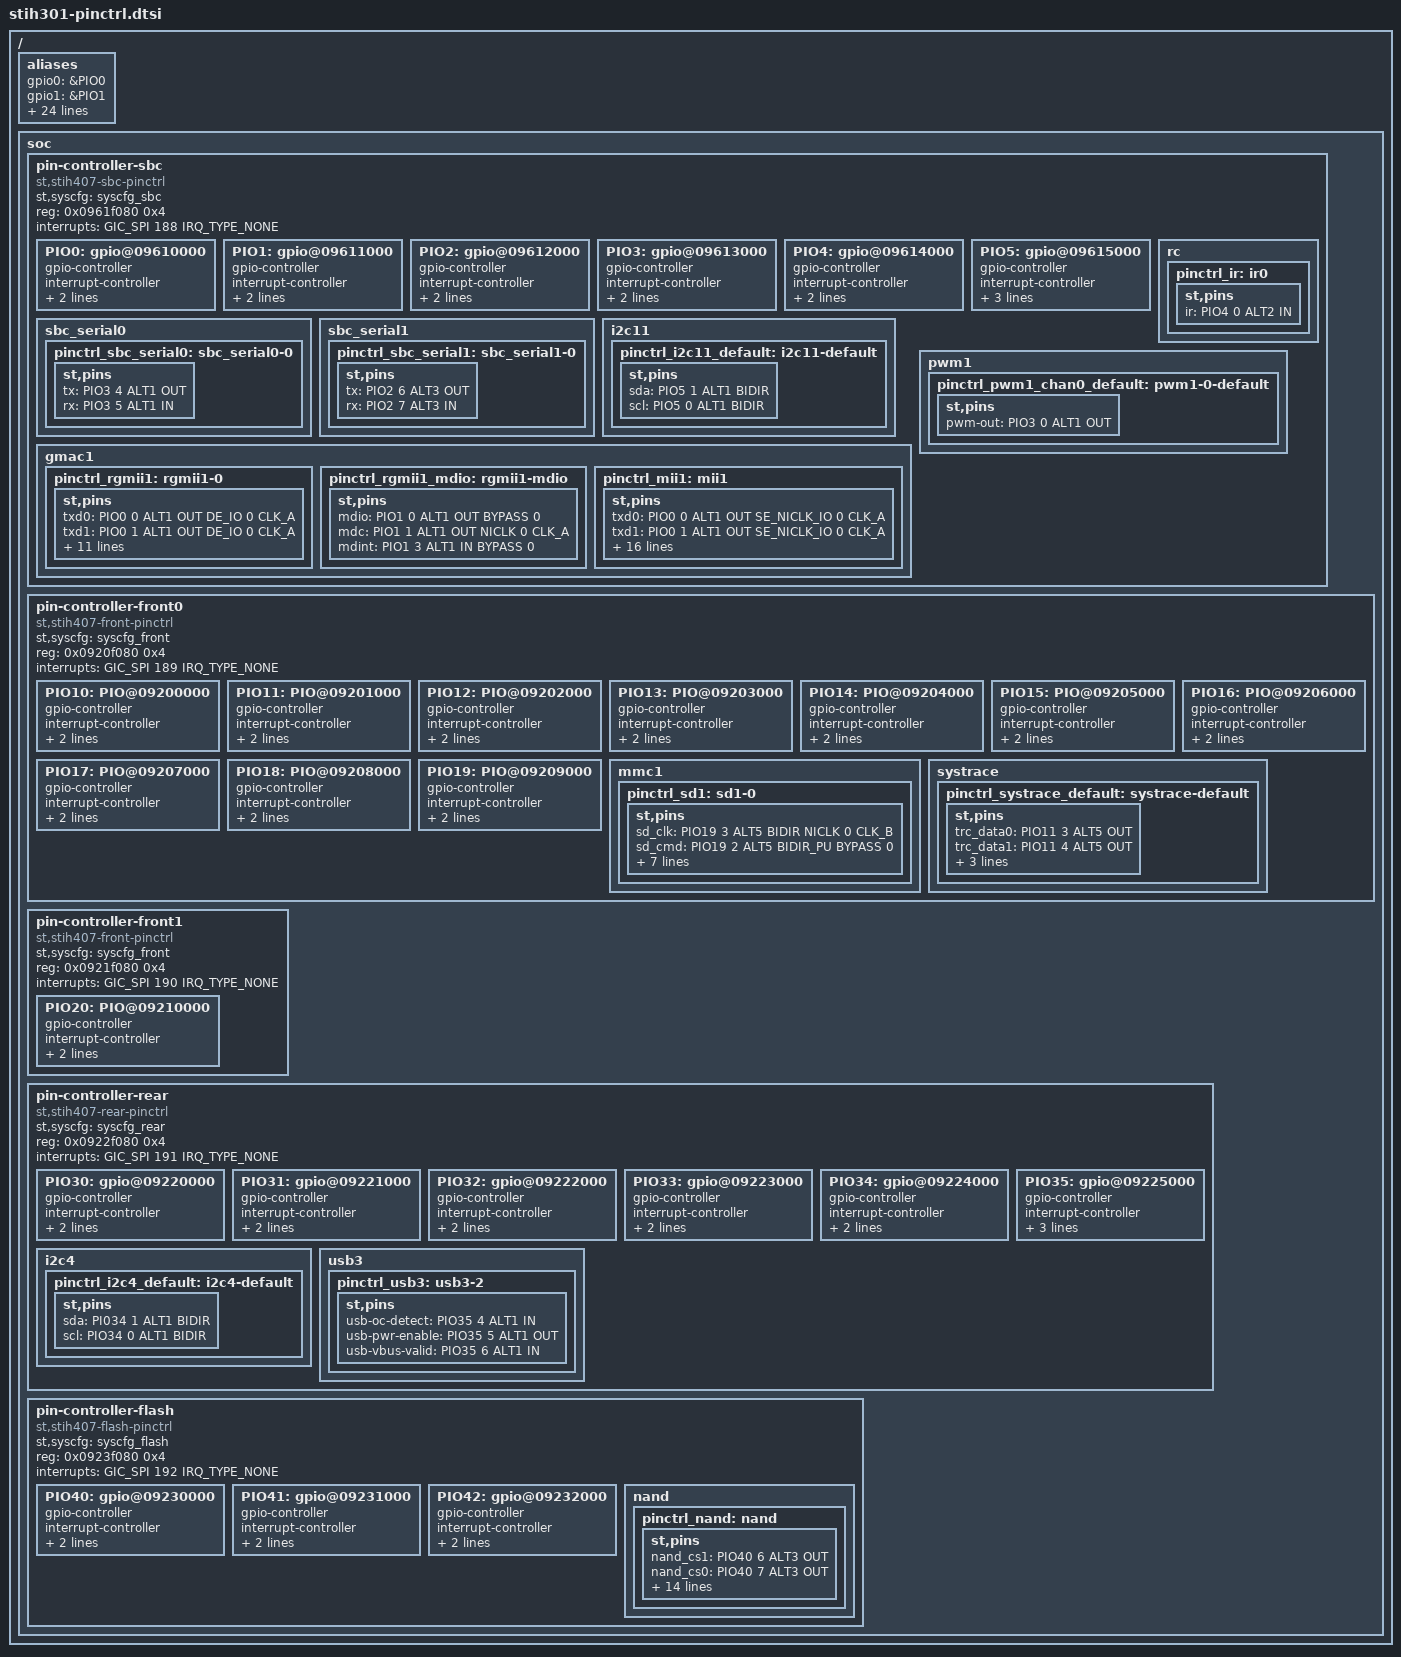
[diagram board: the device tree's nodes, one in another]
/*
 * Copyright (C) 2014 STMicroelectronics Limited.
 * Author: Amelie Herault <amelie.herault@st.com>
 *
 * This program is free software; you can redistribute it and/or modify
 * it under the terms of the GNU General Public License version 2 as
 * publishhed by the Free Software Foundation.
 */
#include <dt-bindings/pinctrl/st-pincfg.h>
#include <dt-bindings/interrupt-controller/arm-gic.h>
/ {

	aliases {
		/* 0-5: PIO_SBC */
		gpio0 = &PIO0;
		gpio1 = &PIO1;
		gpio2 = &PIO2;
		gpio3 = &PIO3;
		gpio4 = &PIO4;
		gpio5 = &PIO5;
		/* 10-19: PIO_FRONT0 */
		gpio6 = &PIO10;
		gpio7 = &PIO11;
		gpio8 = &PIO12;
		gpio9 = &PIO13;
		gpio10 = &PIO14;
		gpio11 = &PIO15;
		gpio12 = &PIO16;
		gpio13 = &PIO17;
		gpio14 = &PIO18;
		gpio15 = &PIO19;
		/* 20: PIO_FRONT1 */
		gpio16 = &PIO20;
		/* 30-35: PIO_REAR */
		gpio17 = &PIO30;
		gpio18 = &PIO31;
		gpio19 = &PIO32;
		gpio20 = &PIO33;
		gpio21 = &PIO34;
		gpio22 = &PIO35;
		/* 40-42: PIO_FLASH */
		gpio23 = &PIO40;
		gpio24 = &PIO41;
		gpio25 = &PIO42;
	};

	soc {
		pin-controller-sbc {
			#address-cells = <1>;
			#size-cells = <1>;
			compatible = "st,stih407-sbc-pinctrl";
			st,syscfg = <&syscfg_sbc>;
			reg = <0x0961f080 0x4>;
			reg-names = "irqmux";
			interrupts = <GIC_SPI 188 IRQ_TYPE_NONE>;
			interrupt-names = "irqmux";
			ranges = <0 0x09610000 0x6000>;

			PIO0: gpio@09610000 {
				gpio-controller;
				#gpio-cells = <2>;
				interrupt-controller;
				#interrupt-cells = <2>;
				reg = <0x0 0x100>;
				st,bank-name = "PIO0";
			};
			PIO1: gpio@09611000 {
				gpio-controller;
				#gpio-cells = <2>;
				interrupt-controller;
				#interrupt-cells = <2>;
				reg = <0x1000 0x100>;
				st,bank-name = "PIO1";
			};
			PIO2: gpio@09612000 {
				gpio-controller;
				#gpio-cells = <2>;
				interrupt-controller;
				#interrupt-cells = <2>;
				reg = <0x2000 0x100>;
				st,bank-name = "PIO2";
			};
			PIO3: gpio@09613000 {
				gpio-controller;
				#gpio-cells = <2>;
				interrupt-controller;
				#interrupt-cells = <2>;
				reg = <0x3000 0x100>;
				st,bank-name = "PIO3";
			};
			PIO4: gpio@09614000 {
				gpio-controller;
				#gpio-cells = <2>;
				interrupt-controller;
				#interrupt-cells = <2>;
				reg = <0x4000 0x100>;
				st,bank-name = "PIO4";
			};

			PIO5: gpio@09615000 {
				gpio-controller;
				#gpio-cells = <2>;
				interrupt-controller;
				#interrupt-cells = <2>;
				reg = <0x5000 0x100>;
				st,bank-name = "PIO5";
				st,retime-pin-mask = <0x3f>;
			};

			rc {
				pinctrl_ir: ir0 {
					st,pins {
						ir = <&PIO4 0 ALT2 IN>;
					};
				};
			};

			/* SBC_ASC0 - UART10 */
			sbc_serial0 {
				pinctrl_sbc_serial0: sbc_serial0-0 {
					st,pins {
						tx = <&PIO3 4 ALT1 OUT>;
						rx = <&PIO3 5 ALT1 IN>;
					};
				};
			};
			/* SBC_ASC1 - UART11 */
			sbc_serial1 {
				pinctrl_sbc_serial1: sbc_serial1-0 {
					st,pins {
						tx = <&PIO2 6 ALT3 OUT>;
						rx = <&PIO2 7 ALT3 IN>;
					};
				};
			};

			i2c11 {
				pinctrl_i2c11_default: i2c11-default {
					st,pins {
						sda = <&PIO5 1 ALT1 BIDIR>;
						scl = <&PIO5 0 ALT1 BIDIR>;
					};
				};
			};

			gmac1 {
				/*
				  Almost all the boards based on STiH407 SoC have an embedded
				  switch where the mdio/mdc have been used for managing the SMI
				  iface via I2C. For this reason these lines can be allocated
				  by using dedicated configuration (in case of there will be a
				  standard PHY transceiver on-board).
				*/
				pinctrl_rgmii1: rgmii1-0 {
					st,pins {

						txd0 = <&PIO0 0 ALT1 OUT DE_IO 0 CLK_A>;
						txd1 = <&PIO0 1 ALT1 OUT DE_IO 0 CLK_A>;
						txd2 = <&PIO0 2 ALT1 OUT DE_IO 0 CLK_A>;
						txd3 = <&PIO0 3 ALT1 OUT DE_IO 0 CLK_A>;
						txen = <&PIO0 5 ALT1 OUT DE_IO 0 CLK_A>;
						rxd0 = <&PIO1 4 ALT1 IN DE_IO 0 CLK_A>;
						rxd1 = <&PIO1 5 ALT1 IN DE_IO 0 CLK_A>;
						rxd2 = <&PIO1 6 ALT1 IN DE_IO 0 CLK_A>;
						rxd3 = <&PIO1 7 ALT1 IN DE_IO 0 CLK_A>;
						rxdv = <&PIO2 0 ALT1 IN DE_IO 0 CLK_A>;
						rxclk = <&PIO2 2 ALT1 IN NICLK 500 CLK_A>;
						clk125 = <&PIO3 7 ALT4 IN NICLK 0 CLK_A>;
						phyclk = <&PIO2 3 ALT4 OUT NICLK 1750 CLK_B>;
					};
				};

				pinctrl_rgmii1_mdio: rgmii1-mdio {
					st,pins {
						mdio = <&PIO1 0 ALT1 OUT BYPASS 0>;
						mdc = <&PIO1 1 ALT1 OUT NICLK 0 CLK_A>;
						mdint = <&PIO1 3 ALT1 IN BYPASS 0>;
					};
				};

				pinctrl_mii1: mii1 {
					st,pins {
						txd0 = <&PIO0 0 ALT1 OUT SE_NICLK_IO 0 CLK_A>;
						txd1 = <&PIO0 1 ALT1 OUT SE_NICLK_IO 0 CLK_A>;
						txd2 = <&PIO0 2 ALT1 OUT SE_NICLK_IO 0 CLK_A>;
						txd3 = <&PIO0 3 ALT1 OUT SE_NICLK_IO 0 CLK_A>;
						txer = <&PIO0 4 ALT1 OUT SE_NICLK_IO 0 CLK_A>;
						txen = <&PIO0 5 ALT1 OUT SE_NICLK_IO 0 CLK_A>;
						col = <&PIO0 7 ALT1 IN BYPASS 1000>;

						mdio = <&PIO1 0 ALT1 OUT BYPASS 1500>;
						mdc = <&PIO1 1 ALT1 OUT NICLK 0 CLK_A>;
						crs = <&PIO1 2 ALT1 IN BYPASS 1000>;
						mdint = <&PIO1 3 ALT1 IN BYPASS 0>;
						rxd0 = <&PIO1 4 ALT1 IN SE_NICLK_IO 0 CLK_A>;
						rxd1 = <&PIO1 5 ALT1 IN SE_NICLK_IO 0 CLK_A>;
						rxd2 = <&PIO1 6 ALT1 IN SE_NICLK_IO 0 CLK_A>;
						rxd3 = <&PIO1 7 ALT1 IN SE_NICLK_IO 0 CLK_A>;

						rxdv = <&PIO2 0 ALT1 IN SE_NICLK_IO 0 CLK_A>;
						rxclk = <&PIO2 2 ALT1 IN NICLK 0 CLK_A>;
						phyclk = <&PIO2 3 ALT1 OUT NICLK 0 CLK_A>;
					};
				};

			};

			pwm1 {
				pinctrl_pwm1_chan0_default: pwm1-0-default {
					st,pins {
						pwm-out = <&PIO3 0 ALT1 OUT>;
					};
				};
			};
		};

		pin-controller-front0 {
			#address-cells = <1>;
			#size-cells = <1>;
			compatible = "st,stih407-front-pinctrl";
			st,syscfg = <&syscfg_front>;
			reg = <0x0920f080 0x4>;
			reg-names = "irqmux";
			interrupts = <GIC_SPI 189 IRQ_TYPE_NONE>;
			interrupt-names = "irqmux";
			ranges = <0 0x09200000 0x10000>;

			PIO10: PIO@09200000 {
				gpio-controller;
				#gpio-cells = <2>;
				interrupt-controller;
				#interrupt-cells = <2>;
				reg = <0x0 0x100>;
				st,bank-name = "PIO10";
			};
			PIO11: PIO@09201000 {
				gpio-controller;
				#gpio-cells = <2>;
				interrupt-controller;
				#interrupt-cells = <2>;
				reg = <0x1000 0x100>;
				st,bank-name = "PIO11";
			};
			PIO12: PIO@09202000 {
				gpio-controller;
				#gpio-cells = <2>;
				interrupt-controller;
				#interrupt-cells = <2>;
				reg = <0x2000 0x100>;
				st,bank-name = "PIO12";
			};
			PIO13: PIO@09203000 {
				gpio-controller;
				#gpio-cells = <2>;
				interrupt-controller;
				#interrupt-cells = <2>;
				reg = <0x3000 0x100>;
				st,bank-name = "PIO13";
			};
			PIO14: PIO@09204000 {
				gpio-controller;
				#gpio-cells = <2>;
				interrupt-controller;
				#interrupt-cells = <2>;
				reg = <0x4000 0x100>;
				st,bank-name = "PIO14";
			};
			PIO15: PIO@09205000 {
				gpio-controller;
				#gpio-cells = <2>;
				interrupt-controller;
				#interrupt-cells = <2>;
				reg = <0x5000 0x100>;
				st,bank-name = "PIO15";
			};
			PIO16: PIO@09206000 {
				gpio-controller;
				#gpio-cells = <2>;
				interrupt-controller;
				#interrupt-cells = <2>;
				reg = <0x6000 0x100>;
				st,bank-name = "PIO16";
			};
			PIO17: PIO@09207000 {
				gpio-controller;
				#gpio-cells = <2>;
				interrupt-controller;
				#interrupt-cells = <2>;
				reg = <0x7000 0x100>;
				st,bank-name = "PIO17";
			};
			PIO18: PIO@09208000 {
				gpio-controller;
				#gpio-cells = <2>;
				interrupt-controller;
				#interrupt-cells = <2>;
				reg = <0x8000 0x100>;
				st,bank-name = "PIO18";
			};
			PIO19: PIO@09209000 {
				gpio-controller;
				#gpio-cells = <2>;
				interrupt-controller;
				#interrupt-cells = <2>;
				reg = <0x9000 0x100>;
				st,bank-name = "PIO19";
			};

			mmc1 {
				pinctrl_sd1: sd1-0 {
					st,pins {
						sd_clk = <&PIO19 3 ALT5 BIDIR NICLK 0 CLK_B>;
						sd_cmd = <&PIO19 2 ALT5 BIDIR_PU BYPASS 0>;
						sd_dat0 = <&PIO19 4 ALT5 BIDIR_PU BYPASS 0>;
						sd_dat1 = <&PIO19 5 ALT5 BIDIR_PU BYPASS 0>;
						sd_dat2 = <&PIO19 6 ALT5 BIDIR_PU BYPASS 0>;
						sd_dat3 = <&PIO19 7 ALT5 BIDIR_PU BYPASS 0>;
						sd_pwren = <&PIO16 7 ALT6 OUT>;
						sd_cd = <&PIO19 0 ALT6 IN_PU>;
						sd_wp = <&PIO19 1 ALT6 IN>;
					};
				};
			};

			systrace {
				pinctrl_systrace_default: systrace-default {
					st,pins {
						trc_data0 = <&PIO11 3 ALT5 OUT>;
						trc_data1 = <&PIO11 4 ALT5 OUT>;
						trc_data2 = <&PIO11 5 ALT5 OUT>;
						trc_data3 = <&PIO11 6 ALT5 OUT>;
						trc_clk   = <&PIO11 7 ALT5 OUT>;
					};
				};
			};
		};

		pin-controller-front1 {
			#address-cells = <1>;
			#size-cells = <1>;
			compatible = "st,stih407-front-pinctrl";
			st,syscfg = <&syscfg_front>;
			reg = <0x0921f080 0x4>;
			reg-names = "irqmux";
			interrupts = <GIC_SPI 190 IRQ_TYPE_NONE>;
			interrupt-names = "irqmux";
			ranges = <0 0x09210000 0x10000>;

			PIO20: PIO@09210000 {
				gpio-controller;
				#gpio-cells = <2>;
				interrupt-controller;
				#interrupt-cells = <2>;
				reg = <0x0 0x100>;
				st,bank-name = "PIO20";
			};
		};

		pin-controller-rear {
			#address-cells = <1>;
			#size-cells = <1>;
			compatible = "st,stih407-rear-pinctrl";
			st,syscfg = <&syscfg_rear>;
			reg = <0x0922f080 0x4>;
			reg-names = "irqmux";
			interrupts = <GIC_SPI 191 IRQ_TYPE_NONE>;
			interrupt-names = "irqmux";
			ranges = <0 0x09220000 0x6000>;

			PIO30: gpio@09220000 {
				gpio-controller;
				#gpio-cells = <2>;
				interrupt-controller;
				#interrupt-cells = <2>;
				reg = <0x0 0x100>;
				st,bank-name = "PIO30";
			};
			PIO31: gpio@09221000 {
				gpio-controller;
				#gpio-cells = <2>;
				interrupt-controller;
				#interrupt-cells = <2>;
				reg = <0x1000 0x100>;
				st,bank-name = "PIO31";
			};
			PIO32: gpio@09222000 {
				gpio-controller;
				#gpio-cells = <2>;
				interrupt-controller;
				#interrupt-cells = <2>;
				reg = <0x2000 0x100>;
				st,bank-name = "PIO32";
			};
			PIO33: gpio@09223000 {
				gpio-controller;
				#gpio-cells = <2>;
				interrupt-controller;
				#interrupt-cells = <2>;
				reg = <0x3000 0x100>;
				st,bank-name = "PIO33";
			};
			PIO34: gpio@09224000 {
				gpio-controller;
				#gpio-cells = <2>;
				interrupt-controller;
				#interrupt-cells = <2>;
				reg = <0x4000 0x100>;
				st,bank-name = "PIO34";
			};
			PIO35: gpio@09225000 {
				gpio-controller;
				#gpio-cells = <2>;
				interrupt-controller;
				#interrupt-cells = <2>;
				reg = <0x5000 0x100>;
				st,bank-name = "PIO35";
				st,retime-pin-mask = <0x7f>;
			};

			i2c4 {
				pinctrl_i2c4_default: i2c4-default {
					st,pins {
						sda = <&PI034 1 ALT1 BIDIR>;
						scl = <&PIO34 0 ALT1 BIDIR>;
					};
				};
			};

			usb3 {
				pinctrl_usb3: usb3-2 {
					st,pins {
						usb-oc-detect = <&PIO35 4 ALT1 IN>;
						usb-pwr-enable = <&PIO35 5 ALT1 OUT>;
						usb-vbus-valid = <&PIO35 6 ALT1 IN>;
					};
				};
			};
		};

		pin-controller-flash {
			#address-cells = <1>;
			#size-cells = <1>;
			compatible = "st,stih407-flash-pinctrl";
			st,syscfg = <&syscfg_flash>;
			reg = <0x0923f080 0x4>;
			reg-names = "irqmux";
			interrupts = <GIC_SPI 192 IRQ_TYPE_NONE>;
			interrupt-names = "irqmux";
			ranges = <0 0x09230000 0x3000>;

			PIO40: gpio@09230000 {
				gpio-controller;
				#gpio-cells = <2>;
				interrupt-controller;
				#interrupt-cells = <2>;
				reg = <0 0x100>;
				st,bank-name = "PIO40";
			};
			PIO41: gpio@09231000 {
				gpio-controller;
				#gpio-cells = <2>;
				interrupt-controller;
				#interrupt-cells = <2>;
				reg = <0x1000 0x100>;
				st,bank-name = "PIO41";
			};
			PIO42: gpio@09232000 {
				gpio-controller;
				#gpio-cells = <2>;
				interrupt-controller;
				#interrupt-cells = <2>;
				reg = <0x2000 0x100>;
				st,bank-name = "PIO42";
			};

			nand {
				pinctrl_nand: nand {
					st,pins {
						nand_cs1 = <&PIO40 6 ALT3 OUT>;
						nand_cs0 = <&PIO40 7 ALT3 OUT>;
						nand_d0 = <&PIO41 0 ALT3 BIDIR>;
						nand_d1 = <&PIO41 1 ALT3 BIDIR>;
						nand_d2 = <&PIO41 2 ALT3 BIDIR>;
						nand_d3 = <&PIO41 3 ALT3 BIDIR>;
						nand_d4 = <&PIO41 4 ALT3 BIDIR>;
						nand_d5 = <&PIO41 5 ALT3 BIDIR>;
						nand_d6 = <&PIO41 6 ALT3 BIDIR>;
						nand_d7 = <&PIO41 7 ALT3 BIDIR>;
						nand_we = <&PIO42 0 ALT3 OUT>;
						nand_dqs = <&PIO42 1 ALT3 OUT>;
						nand_ale = <&PIO42 2 ALT3 OUT>;
						nand_cle = <&PIO42 3 ALT3 OUT>;
						nand_rnb = <&PIO42 4 ALT3 IN>;
						nand_oe = <&PIO42 5 ALT3 OUT>;
					};
				};
			};
		};
	};
};
